# RL6955_IP_SVD register map
Vendor: Realtek
Registers are 32-bit, read-write, reset 0x0 unless marked. A register's access mark holds for its fields unless they carry their own. Offsets are from the block's base; [hi:lo] are bit positions; {n}, {i} and the like mark numbered series.

## DEBUGTIMER_REG
Base 0x40804000
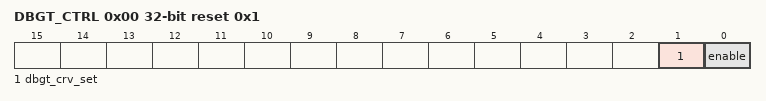
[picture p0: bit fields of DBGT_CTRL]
0x00 DBGT_CTRL access per field reset 0x1 — debugtimer control register
  [1] dbgt_crv_set wo — set dbgt_crv0/1 to dbgtcnt
  [0] enable rw — Debug timer enable. 1: The counter is enabled. 0: The counter is disabled.
0x04 DBGT_CRV0 — debugtimer count register
  [31:0] dbgt_crv0 — dbgtcnt[31:0].Continuing to count from 0 once it's reached 32'Hffffffff
0x08 DBGT_CRV1 — debugtimer count register
  [31:0] dbgt_crv1 — dbgtcnt[63:32].Continuing to count from 0 once it's reached 32'hFFFFFFFF
0x0C DBGT_ATOM_INC ro — debugtimer atom read increase
  [31:0] dbgt_atom_inc — Each read will increase 1 and return to the increased value to bus.
0x10 DBGT_ATOM — debugtimer atom
  [31:0] dbgt_atom — Return the last increased value of atom counter
0x14 DBGT_SCRATCH — debugtimer scratch
  [31:0] dbgt_scratch — Reserved for user use
0x18 REG_DBGTIM_DUMMY reset 0xFFFF — Debug TimerDummy Register

## PMC0_TIMER_REG
Base 0x40805000
Same registers: PMC1_TIMER_REG 0x41007000
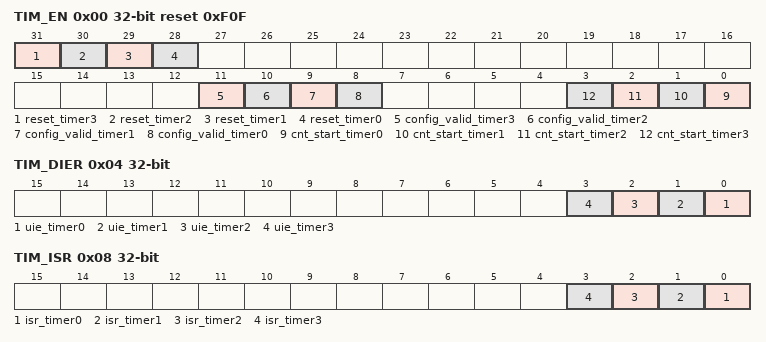
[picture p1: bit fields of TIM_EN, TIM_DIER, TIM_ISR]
0x00 TIM_EN access per field reset 0xF0F — TIM enable register
  [31] reset_timer3 wo — Writing 1 will cause a pulse reset timer1. Please wait for 3 work clk before new timer configuration 1: valid 0: not valid
  [30] reset_timer2 wo — Writing 1 will cause a pulse reset timer1. Please wait for 3 work clk before new timer configuration 1: valid 0: not valid
  [29] reset_timer1 wo — Writing 1 will cause a pulse reset timer1. Please wait for 3 work clk before new timer configuration 1: valid 0: not valid
  [28] reset_timer0 wo — Writing 1 will cause a pulse reset timer0. Please wait for 3 work clk before new timer configuration 1: valid 0: not valid
  [11] config_valid_timer3 ro — TIM_SET configuration valid or not. 1: valid 0: not valid if compare option enable, 1: vaild value is seted 0: set option is on going
  [10] config_valid_timer2 ro — TIM_SET configuration valid or not 1: valid 0: not valid
  [9] config_valid_timer1 ro — TIM_SET configuration valid or not 1: valid 0: not valid
  [8] config_valid_timer0 ro — TIM_SET configuration valid or not 1: valid 0: not valid
  [n] cnt_start_timer{n} rw (n=0..3) — enable the timer{n} counter. 1:enable 0:disable
0x04 TIM_DIER — TIM interupt enable register
  [n] uie_timer{n} (n=0..3) — 1: enable update interrupt 0: disable update interrupt
0x08 TIM_ISR ro — TIM interrupt status register
  [n] isr_timer{n} (n=0..3) — Timer interrupt status 0: no interrupt 1: interrupt occurs Write 1 to clear interrupts in interrupt handler.
{0xC+4i} TIM_CNT{i} ro reset 0xFFFFFFFF (i=0..3) — TIM counter{i}
  [31:0] cnt{i} — counter value, counter will stop automatically when it counts down to zero.
{0x1C+4i} TIM_SET{i} (i=0..3) — TIM set register{i}
  [31:0] tim_set{i} — Set a countdown value. This value come into force when TIM_EN register bit is enabled. counter will count down from this value immediately.
0x2C TIM_com_en reset 0xF — TIM compare register
  [3:0] com_en — enable compare option.The set cnt value takes effect only when it is greater than the actual cnt value 0:disable 1:enable [0] : control tim0 set ...... [3]: control tim3 set
0x30 PMCTIM_DUMMY reset 0xFFFF — PMCTimer Dummy Register

## TIMER4_REG
Base 0x40806000
Same registers: TIMER5_REG 0x40806200, TIMER0_REG 0x41008000, TIMER1_REG 0x41008200, TIMER2_REG 0x41008400, TIMER3_REG 0x41008600
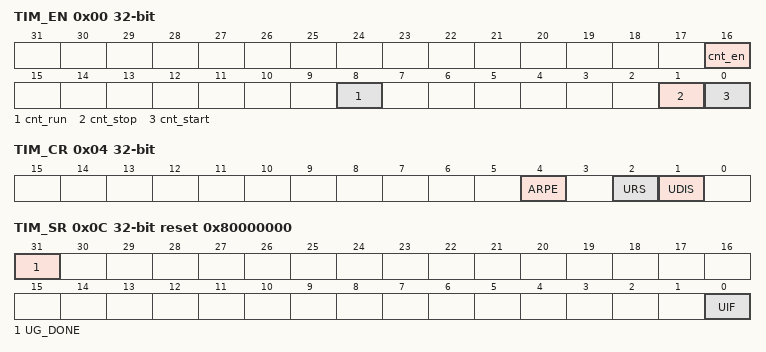
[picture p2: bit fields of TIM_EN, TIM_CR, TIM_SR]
0x00 TIM_EN access per field — TIM enable register
  [16] cnt_en ro — counter working status * 0: counter is stoppped * 1: counter is working
  [8] cnt_run ro — counter run status * 0: counter is disabled * 1: counter is enabled
  [1] cnt_stop wo — disable the counter. Poll CNT_RUN to see the counter status. If CNT_RUN is 0, it means that the counter has been disabled internally.
  [0] cnt_start wo — enable the counter. Poll CNT_RUN to see the counter status. If CNT_RUN is 1, it means that the counter has been enabled internally.
0x04 TIM_CR — TIM control register
  [4] ARPE — enable auto-reload preloading * 0: TIM_ARR register is not buffered * 1: TIM_ARR register is buffered
  [2] URS — update request source * 0: counter overflow and setting the UG bit * 1: counter overflow
  [1] UDIS — disable UEV. Shadow registers keep their values. Otherwise, buffered registers are then loaded with their preload values when UEV happen.
0x08 TIM_DIER — TIM interupt enable register
  [0] UIE — enable update interrupt
0x0C TIM_SR ro reset 0x80000000 — TIM status register
  [31] UG_DONE — UG operation status This bit is cleared by hardware when the UG bit in the TIMx_EGR register is set. When the UG operation is done, hardware set this bit to '1'. So, software can poll this bit to see the UG operation status.
  [0] UIF — update interrupt flag
0x10 TIM_EGR wo — TIM event generation register
  [0] UG — update generation. Re-initialize the counter and generate an update of registers. Note that the prescaler counter is cleared too.(anyway the prescaler ratio is not affected)
0x14 TIM_CNT ro — TIM counter
  [31:0] CNT — counter value
0x1C TIM_ARR reset 0xFFFFFFFF — TIM auto-reload register
  [31:0] ARR — the value to be loaded in the actual auto-reload register. It can be preloaded by setting ARPE bit in TIM_CR.
0x20 TIM_SEC — TIM security control register
  [0] SEC — Secure timer enable. 0: This is a non-secure timer. All its registers except TIMx_SEC can be accessed from both secure and non-secure address. As a result, both secure and non-secure code can access it. 1: This is a secure timer. All its registers can only be accessed from secure address. As a result, only secure code can access it. Non-secure code can't access it through non-secure address.
0x24 REG_TIM_BASIC_DUMMY reset 0xFFFF — Timer Baisc Dummy Register
